# STM32H743 register map
File version: 2.4
CPU: CM7 r0p1, little endian, MPU, FPU, 4 interrupt priority bits
Registers are 32-bit, read-write, reset 0x0 unless marked. A register's access mark holds for its fields unless they carry their own. Offsets are from the block's base; [hi:lo] are bit positions.

## TIM16 — 通用定时器
Base 0x40014400
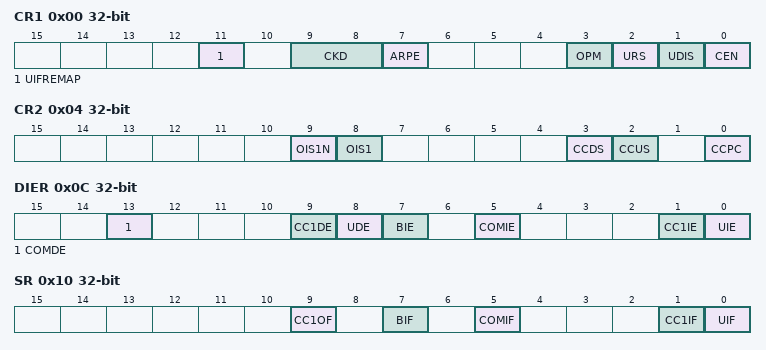
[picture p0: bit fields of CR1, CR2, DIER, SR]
0x00 CR1 — 控制寄存器 1
  [11] UIFREMAP — UIF 状态位重映射
  [9:8] CKD — 时钟分频
  [7] ARPE — 自动重载预装载使能
  [3] OPM — 单脉冲模式
  [2] URS — 更新请求源
  [1] UDIS — 更新禁用
  [0] CEN — 计数器使能
0x04 CR2 — 控制寄存器 2
  [9] OIS1N — 互补输出空闲状态 1
  [8] OIS1 — 输出空闲状态 1
  [3] CCDS — 捕获/比较 DMA 选择
  [2] CCUS — 捕获/比较控制更新选择
  [0] CCPC — 捕获/比较预装载控制
0x0C DIER — DMA/中断使能寄存器
  [13] COMDE — COM DMA 请求使能
  [9] CC1DE — 捕获/比较 1 DMA 请求使能
  [8] UDE — 更新 DMA 请求使能
  [7] BIE — 刹车中断使能
  [5] COMIE — COM 中断使能
  [1] CC1IE — 捕获/比较 1 中断使能
  [0] UIE — 更新中断使能
0x10 SR — 状态寄存器
  [9] CC1OF — 捕获/比较 1 重复捕获标志
  [7] BIF — 刹车中断标志
  [5] COMIF — COM 中断标志
  [1] CC1IF — 捕获/比较 1 中断标志
  [0] UIF — 更新中断标志
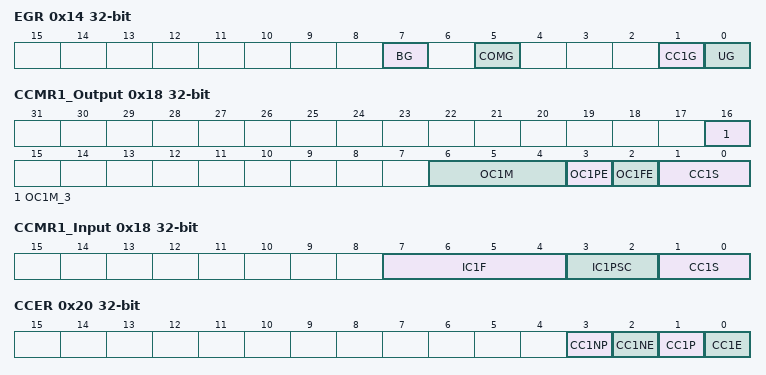
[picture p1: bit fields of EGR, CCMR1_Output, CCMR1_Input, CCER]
0x14 EGR wo — 事件生成寄存器
  [7] BG — 刹车事件生成
  [5] COMG — 捕获/比较控制更新生成
  [1] CC1G — 捕获/比较 1 事件生成
  [0] UG — 更新事件生成
0x18 CCMR1_Output — 捕获/比较模式寄存器（输出模式）
  [16] OC1M_3 — 输出比较 1 模式（位 3）
  [6:4] OC1M — 输出比较 1 模式
  [3] OC1PE — 输出比较 1 预装载使能
  [2] OC1FE — 输出比较 1 快速使能
  [1:0] CC1S — 捕获/比较 1 选择
0x18 CCMR1_Input (alternate view of CCMR1_Output) — 捕获/比较模式寄存器 1（输入模式）
  [7:4] IC1F — 输入捕获 1 滤波器
  [3:2] IC1PSC — 输入捕获 1 预分频器
  [1:0] CC1S — 捕获/比较 1 选择
0x20 CCER — 捕获/比较使能寄存器
  [3] CC1NP — 捕获/比较 1 互补输出极性
  [2] CC1NE — 捕获/比较 1 互补输出使能
  [1] CC1P — 捕获/比较 1 输出极性
  [0] CC1E — 捕获/比较 1 输出使能
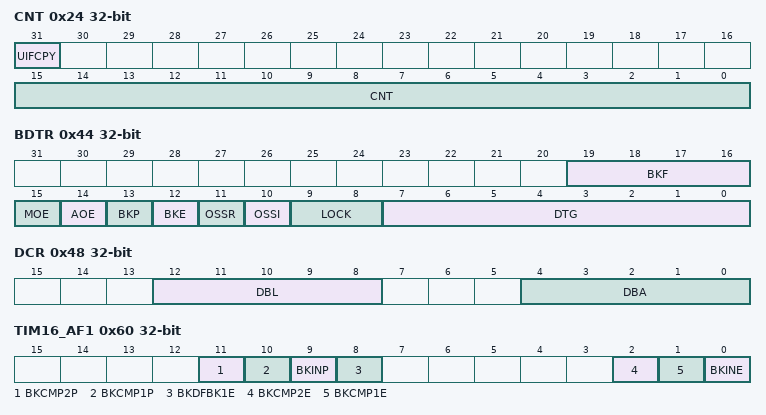
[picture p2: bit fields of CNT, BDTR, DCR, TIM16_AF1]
0x24 CNT access per field — 计数器
  [31] UIFCPY ro — UIF 复制
  [15:0] CNT rw — 计数器值
0x28 PSC — 预分频器
  [15:0] PSC — 预分频器值
0x2C ARR — 自动重载寄存器
  [15:0] ARR — 自动重载值
0x30 RCR — 重复计数器寄存器
  [7:0] REP — 重复计数器值
0x34 CCR1 — 捕获/比较寄存器 1
  [15:0] CCR1 — 捕获/比较 1 值
0x44 BDTR — 刹车与死区寄存器
  [19:16] BKF — 刹车滤波器
  [15] MOE — 主输出使能
  [14] AOE — 自动输出使能
  [13] BKP — 刹车极性
  [12] BKE — 刹车使能
  [11] OSSR — 运行模式关断状态选择
  [10] OSSI — 空闲模式关断状态选择
  [9:8] LOCK — 锁定配置
  [7:0] DTG — 死区发生器设置
0x48 DCR — DMA 控制寄存器
  [12:8] DBL — DMA 突发长度
  [4:0] DBA — DMA 基址
0x4C DMAR — DMA 全传输地址
  [15:0] DMAB — DMA 突发访问寄存器
0x60 TIM16_AF1 — TIM16 复用功能寄存器 1
  [11] BKCMP2P — 刹车 COMP2 输入极性
  [10] BKCMP1P — 刹车 COMP1 输入极性
  [9] BKINP — 刹车 BKIN 输入极性
  [8] BKDFBK1E — 刹车 DFSDM1 断路[1] 使能
  [2] BKCMP2E — 刹车 COMP2 使能
  [1] BKCMP1E — 刹车 COMP1 使能
  [0] BKINE — 刹车 BKIN 输入使能
0x68 TIM16_TISEL — TIM16 输入选择寄存器
  [3:0] TI1SEL — 选择 TI1[0] 至 TI1[15] 输入

## TIM17 — 通用定时器
Base 0x40014800
Registers as TIM16 (with TIM16 read as TIM17); these are added or differ:
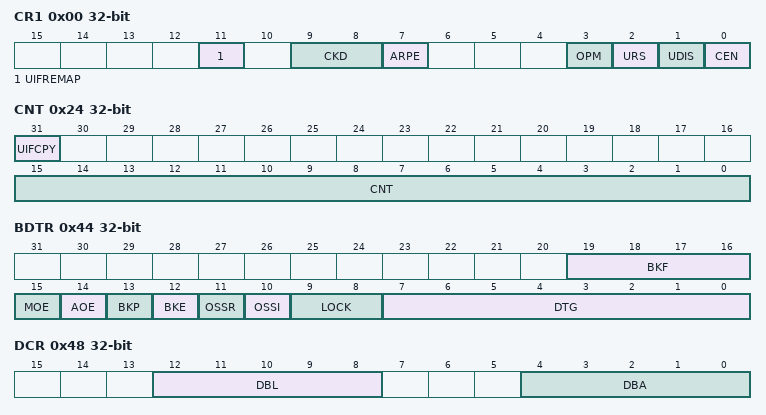
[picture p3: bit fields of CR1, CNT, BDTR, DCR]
0x00 CR1 — 控制寄存器 1
  [11] UIFREMAP — UIF 状态位重映射
  [9:8] CKD — 时钟分频
  [7] ARPE — 自动重装载预装载使能
  [3] OPM — 单脉冲模式
  [2] URS — 更新请求源
  [1] UDIS — 更新禁止
  [0] CEN — 计数器使能
0x24 CNT access per field — 计数器
  [31] UIFCPY ro — UIF 副本
  [15:0] CNT rw — 计数器值
0x2C ARR — 自动重装载寄存器
  [15:0] ARR — 自动重装载值
0x44 BDTR — 刹车与死区寄存器
  [19:16] BKF — 刹车滤波器
  [15] MOE — 主输出使能
  [14] AOE — 自动输出使能
  [13] BKP — 刹车极性
  [12] BKE — 刹车使能
  [11] OSSR — 运行模式关闭状态选择
  [10] OSSI — 空闲模式关闭状态选择
  [9:8] LOCK — 锁定配置
  [7:0] DTG — 死区发生器设置
0x48 DCR — DMA 控制寄存器
  [12:8] DBL — DMA 突发长度
  [4:0] DBA — DMA 基地址
0x4C DMAR — DMA 全传输地址寄存器
  [15:0] DMAB — DMA 突发访问寄存器
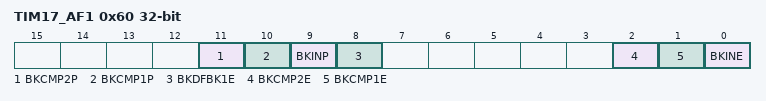
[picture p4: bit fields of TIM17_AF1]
0x60 TIM17_AF1 — TIM17 复用功能寄存器 1
  [11] BKCMP2P — 刹车 COMP2 输入极性
  [10] BKCMP1P — 刹车 COMP1 输入极性
  [9] BKINP — 刹车 BKIN 输入极性
  [8] BKDFBK1E — 刹车 DFSDM1 刹车[1] 使能
  [2] BKCMP2E — 刹车 COMP2 使能
  [1] BKCMP1E — 刹车 COMP1 使能
  [0] BKINE — 刹车 BKIN 输入使能

## TIM15 — 通用定时器
Base 0x40014000
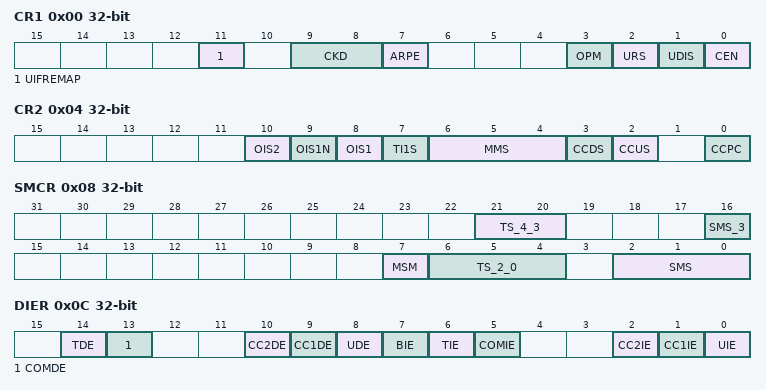
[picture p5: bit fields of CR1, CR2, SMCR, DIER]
0x00 CR1 — 控制寄存器 1
  [11] UIFREMAP — UIF 状态位重映射
  [9:8] CKD — 时钟分频
  [7] ARPE — 自动重载预装载使能
  [3] OPM — 单脉冲模式
  [2] URS — 更新请求源
  [1] UDIS — 更新禁用
  [0] CEN — 计数器使能
0x04 CR2 — 控制寄存器 2
  [10] OIS2 — 输出空闲状态 2
  [9] OIS1N — 互补输出空闲状态 1
  [8] OIS1 — 输出空闲状态 1
  [7] TI1S — TI1 选择
  [6:4] MMS — 主模式选择
  [3] CCDS — 捕获/比较 DMA 选择
  [2] CCUS — 捕获/比较控制更新选择
  [0] CCPC — 捕获/比较预装载控制
0x08 SMCR — 从模式控制寄存器
  [21:20] TS_4_3 — 触发选择 - 位 4:3
  [16] SMS_3 — 从模式选择位 3
  [7] MSM — 主/从模式
  [6:4] TS_2_0 — 触发选择
  [2:0] SMS — 从模式选择
0x0C DIER — DMA/中断使能寄存器
  [14] TDE — 触发 DMA 请求使能
  [13] COMDE — COM DMA 请求使能
  [10] CC2DE — 捕获/比较 2 DMA 请求使能
  [9] CC1DE — 捕获/比较 1 DMA 请求使能
  [8] UDE — 更新 DMA 请求使能
  [7] BIE — 刹车中断使能
  [6] TIE — 触发中断使能
  [5] COMIE — COM 中断使能
  [2] CC2IE — 捕获/比较 2 中断使能
  [1] CC1IE — 捕获/比较 1 中断使能
  [0] UIE — 更新中断使能
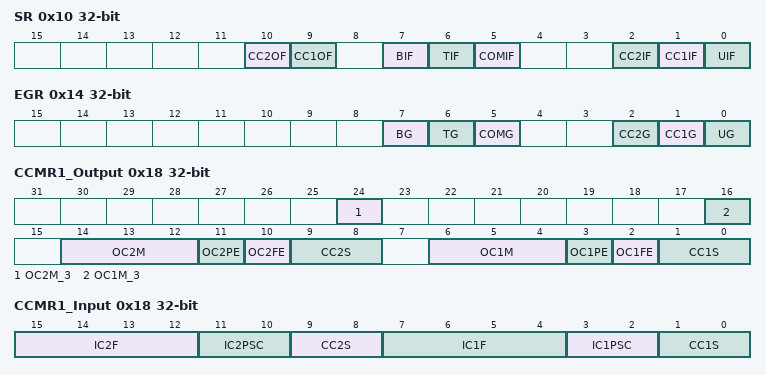
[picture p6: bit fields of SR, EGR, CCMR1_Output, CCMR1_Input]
0x10 SR — 状态寄存器
  [10] CC2OF — 捕获/比较 2 重复捕获标志
  [9] CC1OF — 捕获/比较 1 重复捕获标志
  [7] BIF — 刹车中断标志
  [6] TIF — 触发中断标志
  [5] COMIF — COM 中断标志
  [2] CC2IF — 捕获/比较 2 中断标志
  [1] CC1IF — 捕获/比较 1 中断标志
  [0] UIF — 更新中断标志
0x14 EGR wo — 事件生成寄存器
  [7] BG — 刹车事件生成
  [6] TG — 触发事件生成
  [5] COMG — 捕获/比较控制更新生成
  [2] CC2G — 捕获/比较 2 生成
  [1] CC1G — 捕获/比较 1 生成
  [0] UG — 更新生成
0x18 CCMR1_Output — 捕获/比较模式寄存器（输出模式）
  [24] OC2M_3 — 输出比较 2 模式位 3
  [16] OC1M_3 — 输出比较 1 模式位 3
  [14:12] OC2M — 输出比较 2 模式
  [11] OC2PE — 输出比较 2 预装载使能
  [10] OC2FE — 输出比较 2 快速使能
  [9:8] CC2S — 捕获/比较 2 选择
  [6:4] OC1M — 输出比较 1 模式
  [3] OC1PE — 输出比较 1 预装载使能
  [2] OC1FE — 输出比较 1 快速使能
  [1:0] CC1S — 捕获/比较 1 选择
0x18 CCMR1_Input (alternate view of CCMR1_Output) — 捕获/比较模式寄存器 1（输入模式）
  [15:12] IC2F — 输入捕获 2 滤波器
  [11:10] IC2PSC — 输入捕获 2 预分频器
  [9:8] CC2S — 捕获/比较 2 选择
  [7:4] IC1F — 输入捕获 1 滤波器
  [3:2] IC1PSC — 输入捕获 1 预分频器
  [1:0] CC1S — 捕获/比较 1 选择
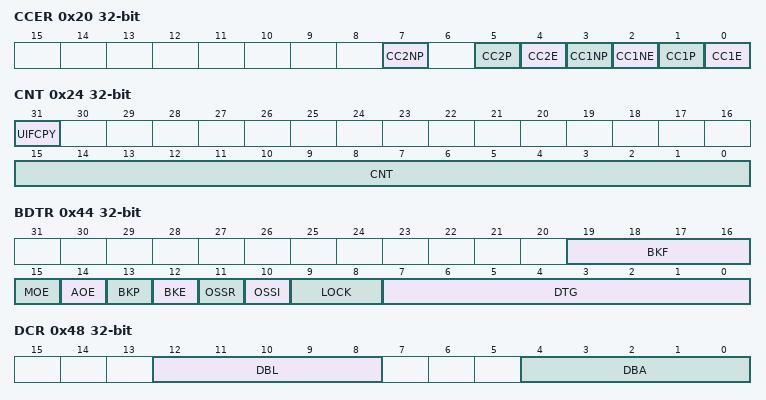
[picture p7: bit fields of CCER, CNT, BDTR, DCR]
0x20 CCER — 捕获/比较使能寄存器
  [7] CC2NP — 捕获/比较 2 互补输出极性
  [5] CC2P — 捕获/比较 2 输出极性
  [4] CC2E — 捕获/比较 2 输出使能
  [3] CC1NP — 捕获/比较 1 互补输出极性
  [2] CC1NE — 捕获/比较 1 互补输出使能
  [1] CC1P — 捕获/比较 1 输出极性
  [0] CC1E — 捕获/比较 1 输出使能
0x24 CNT access per field — 计数器
  [31] UIFCPY ro — UIF 副本
  [15:0] CNT rw — 计数器值
0x28 PSC — 预分频器
  [15:0] PSC — 预分频器值
0x2C ARR — 自动重载寄存器
  [15:0] ARR — 自动重载值
0x30 RCR — 重复计数器寄存器
  [7:0] REP — 重复计数器值
0x34 CCR1 — 捕获/比较寄存器 1
  [15:0] CCR1 — 捕获/比较 1 值
0x38 CCR2 — 捕获/比较寄存器 2
  [15:0] CCR2 — 捕获/比较 2 值
0x44 BDTR — 刹车与死区寄存器
  [19:16] BKF — 刹车滤波器
  [15] MOE — 主输出使能
  [14] AOE — 自动输出使能
  [13] BKP — 刹车极性
  [12] BKE — 刹车使能
  [11] OSSR — 运行模式关闭状态选择
  [10] OSSI — 空闲模式关闭状态选择
  [9:8] LOCK — 锁定配置
  [7:0] DTG — 死区发生器设置
0x48 DCR — DMA 控制寄存器
  [12:8] DBL — DMA 突发长度
  [4:0] DBA — DMA 基地址
0x4C DMAR — DMA 全传输地址寄存器
  [15:0] DMAB — DMA 突发访问寄存器
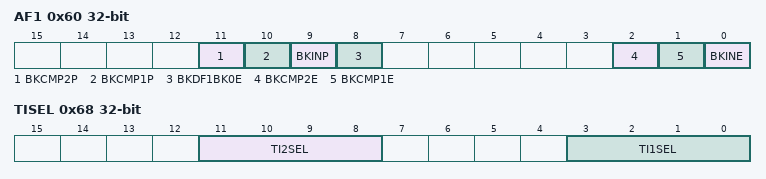
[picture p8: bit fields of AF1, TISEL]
0x60 AF1 — TIM15 复用功能寄存器 1
  [11] BKCMP2P — BRK COMP2 输入极性
  [10] BKCMP1P — BRK COMP1 输入极性
  [9] BKINP — BRK BKIN 输入极性
  [8] BKDF1BK0E — BRK DFSDM1 刹车[0] 使能
  [2] BKCMP2E — BRK COMP2 使能
  [1] BKCMP1E — BRK COMP1 使能
  [0] BKINE — BRK BKIN 输入使能
0x68 TISEL — TIM15 输入选择寄存器
  [11:8] TI2SEL — 选择 TI2[0] 至 TI2[15] 输入
  [3:0] TI1SEL — 选择 TI1[0] 至 TI1[15] 输入
